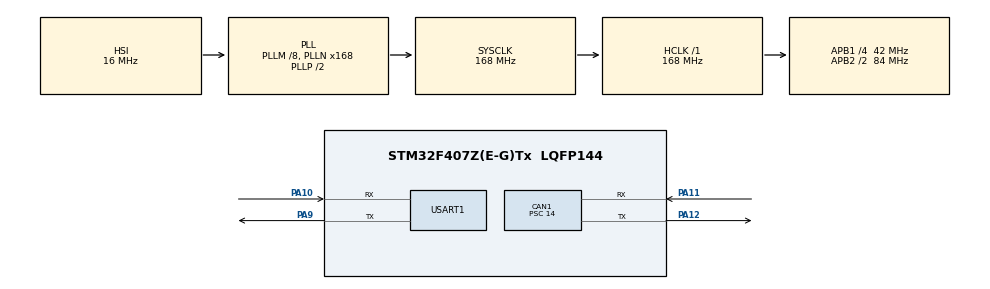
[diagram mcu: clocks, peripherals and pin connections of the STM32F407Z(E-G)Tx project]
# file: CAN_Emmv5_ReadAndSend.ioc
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CAN1.ABOM=ENABLE
CAN1.BS1=CAN_BS1_4TQ
CAN1.CalculateBaudRate=499999
CAN1.CalculateTimeBit=2000
CAN1.CalculateTimeQuantum=333.33333333333337
CAN1.Prescaler=14
Dma.MEMTOMEM.0.Direction=DMA_MEMORY_TO_MEMORY
Dma.MEMTOMEM.0.FIFOMode=DMA_FIFOMODE_ENABLE
Dma.MEMTOMEM.0.FIFOThreshold=DMA_FIFO_THRESHOLD_FULL
Dma.MEMTOMEM.0.Instance=DMA2_Stream0
Dma.MEMTOMEM.0.MemBurst=DMA_MBURST_SINGLE
Dma.MEMTOMEM.0.MemDataAlignment=DMA_MDATAALIGN_BYTE
Dma.MEMTOMEM.0.MemInc=DMA_MINC_ENABLE
Dma.MEMTOMEM.0.Mode=DMA_NORMAL
Dma.MEMTOMEM.0.PeriphBurst=DMA_PBURST_SINGLE
Dma.MEMTOMEM.0.PeriphDataAlignment=DMA_PDATAALIGN_BYTE
Dma.MEMTOMEM.0.PeriphInc=DMA_PINC_ENABLE
Dma.MEMTOMEM.0.Priority=DMA_PRIORITY_LOW
Dma.Request0=MEMTOMEM
Mcu.Family=STM32F4
Mcu.Name=STM32F407Z(E-G)Tx
Mcu.Package=LQFP144
NVIC.CAN1_RX0_IRQn=true\:0\:0\:false\:false\:true\:true\:true\:true
NVIC.PriorityGroup=NVIC_PRIORITYGROUP_4
PA10.Mode=Asynchronous
PA10.Signal=USART1_RX
PA11.Mode=CAN_Activate
PA11.Signal=CAN1_RX
PA12.Mode=CAN_Activate
PA12.Signal=CAN1_TX
PA13.Mode=Serial_Wire
PA13.Signal=SYS_JTMS-SWDIO
PA14.Mode=Serial_Wire
PA14.Signal=SYS_JTCK-SWCLK
PA9.Mode=Asynchronous
PA9.Signal=USART1_TX
PC14-OSC32_IN.Mode=LSE-External-Oscillator
PC14-OSC32_IN.Signal=RCC_OSC32_IN
PC15-OSC32_OUT.Mode=LSE-External-Oscillator
PC15-OSC32_OUT.Signal=RCC_OSC32_OUT
PH0-OSC_IN.Mode=HSE-External-Oscillator
PH0-OSC_IN.Signal=RCC_OSC_IN
PH1-OSC_OUT.Mode=HSE-External-Oscillator
PH1-OSC_OUT.Signal=RCC_OSC_OUT
ProjectManager.HeapSize=0x200
ProjectManager.StackSize=0x400
ProjectManager.TargetToolchain=MDK-ARM V5.32
RCC.48MHZClocksFreq_Value=84000000
RCC.AHBFreq_Value=168000000
RCC.APB1CLKDivider=RCC_HCLK_DIV4
RCC.APB1Freq_Value=42000000
RCC.APB1TimFreq_Value=84000000
RCC.APB2CLKDivider=RCC_HCLK_DIV2
RCC.APB2Freq_Value=84000000
RCC.APB2TimFreq_Value=168000000
RCC.CortexFreq_Value=168000000
RCC.HCLKFreq_Value=168000000
RCC.HSE_VALUE=25000000
RCC.HSI_VALUE=16000000
RCC.PLLM=8
RCC.PLLN=168
RCC.SYSCLKFreq_VALUE=168000000
RCC.SYSCLKSource=RCC_SYSCLKSOURCE_PLLCLK
RCC.VCOOutputFreq_Value=336000000
USART1.VirtualMode=VM_ASYNC
board=custom

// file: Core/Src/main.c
/* USER CODE BEGIN Header */
/**
  ******************************************************************************
  * @file           : main.c
  * @brief          : Main program body
  ******************************************************************************
  * @attention
  *
  * Copyright (c) 2025 STMicroelectronics.
  * All rights reserved.
  *
  * This software is licensed under terms that can be found in the LICENSE file
  * in the root directory of this software component.
  * If no LICENSE file comes with this software, it is provided AS-IS.
  *
  ******************************************************************************
  */
/* USER CODE END Header */
#include "main.h"
#include "can.h"
#include "dma.h"
#include "usart.h"
#include "gpio.h"

/* USER CODE BEGIN Includes */
#include "EmmV5.h"
/* USER CODE END Includes */

/* USER CODE BEGIN PV */
float pos = 0.0f, Motor_Cur_Pos = 0.0f;
/* USER CODE END PV */

void SystemClock_Config(void);

int main(void)
{

  /* MCU Configuration--------------------------------------------------------*/

  /* Reset of all peripherals, Initializes the Flash interface and the Systick. */
  HAL_Init();

  /* Configure the system clock */
  SystemClock_Config();

  /* Initialize all configured peripherals */
  MX_GPIO_Init();
  MX_DMA_Init();
  MX_CAN1_Init();
  MX_USART1_UART_Init();
  /* USER CODE BEGIN 2 */
	USER_CAN1_Filter_Init();
	if(HAL_CAN_Start(&hcan1) != HAL_OK) { Error_Handler(); }	// 启动CAN控制器
	if(HAL_CAN_ActivateNotification(&hcan1, CAN_IT_RX_FIFO0_MSG_PENDING) != HAL_OK) { Error_Handler(); }	// 使能CAN控制器接收中断
	HAL_Delay(2000);
	Emm_V5_Pos_Control(1, 0, 1000, 0, 3200, 0, 0);

	HAL_Delay(2000);
	Emm_V5_Read_Sys_Params(1, S_CPOS);
  /* USER CODE END 2 */

  /* Infinite loop */
  while (1)
  {

    /* USER CODE BEGIN 3 */
		if (can.rxFrameFlag)
		{
				can.rxFrameFlag = false;  // 清标志
				// 处理 can.rxData 中的数据
				printf("can.buffer[%d,%d,%d,%d,%d,%d,%d,%d]\n",can.rxData[0],can.rxData[2],can.rxData[3],can.rxData[4],can.rxData[5],can.rxData[6],can.rxData[7],can.rxData[8]);
		}
  }
  /* USER CODE END 3 */
}

void SystemClock_Config(void)
{
  RCC_OscInitTypeDef RCC_OscInitStruct = {0};
  RCC_ClkInitTypeDef RCC_ClkInitStruct = {0};

  /** Configure the main internal regulator output voltage
  */
  __HAL_RCC_PWR_CLK_ENABLE();
  __HAL_PWR_VOLTAGESCALING_CONFIG(PWR_REGULATOR_VOLTAGE_SCALE1);

  /** Initializes the RCC Oscillators according to the specified parameters
  * in the RCC_OscInitTypeDef structure.
  */
  RCC_OscInitStruct.OscillatorType = RCC_OSCILLATORTYPE_HSI;
  RCC_OscInitStruct.HSIState = RCC_HSI_ON;
  RCC_OscInitStruct.HSICalibrationValue = RCC_HSICALIBRATION_DEFAULT;
  RCC_OscInitStruct.PLL.PLLState = RCC_PLL_ON;
  RCC_OscInitStruct.PLL.PLLSource = RCC_PLLSOURCE_HSI;
  RCC_OscInitStruct.PLL.PLLM = 8;
  RCC_OscInitStruct.PLL.PLLN = 168;
  RCC_OscInitStruct.PLL.PLLP = RCC_PLLP_DIV2;
  RCC_OscInitStruct.PLL.PLLQ = 4;
  if (HAL_RCC_OscConfig(&RCC_OscInitStruct) != HAL_OK)
  {
    Error_Handler();
  }

  /** Initializes the CPU, AHB and APB buses clocks
  */
  RCC_ClkInitStruct.ClockType = RCC_CLOCKTYPE_HCLK|RCC_CLOCKTYPE_SYSCLK
                              |RCC_CLOCKTYPE_PCLK1|RCC_CLOCKTYPE_PCLK2;
  RCC_ClkInitStruct.SYSCLKSource = RCC_SYSCLKSOURCE_PLLCLK;
  RCC_ClkInitStruct.AHBCLKDivider = RCC_SYSCLK_DIV1;
  RCC_ClkInitStruct.APB1CLKDivider = RCC_HCLK_DIV4;
  RCC_ClkInitStruct.APB2CLKDivider = RCC_HCLK_DIV2;

  if (HAL_RCC_ClockConfig(&RCC_ClkInitStruct, FLASH_LATENCY_5) != HAL_OK)
  {
    Error_Handler();
  }
}

void Error_Handler(void)
{
  __disable_irq();
  while (1)
  {
  }
}
